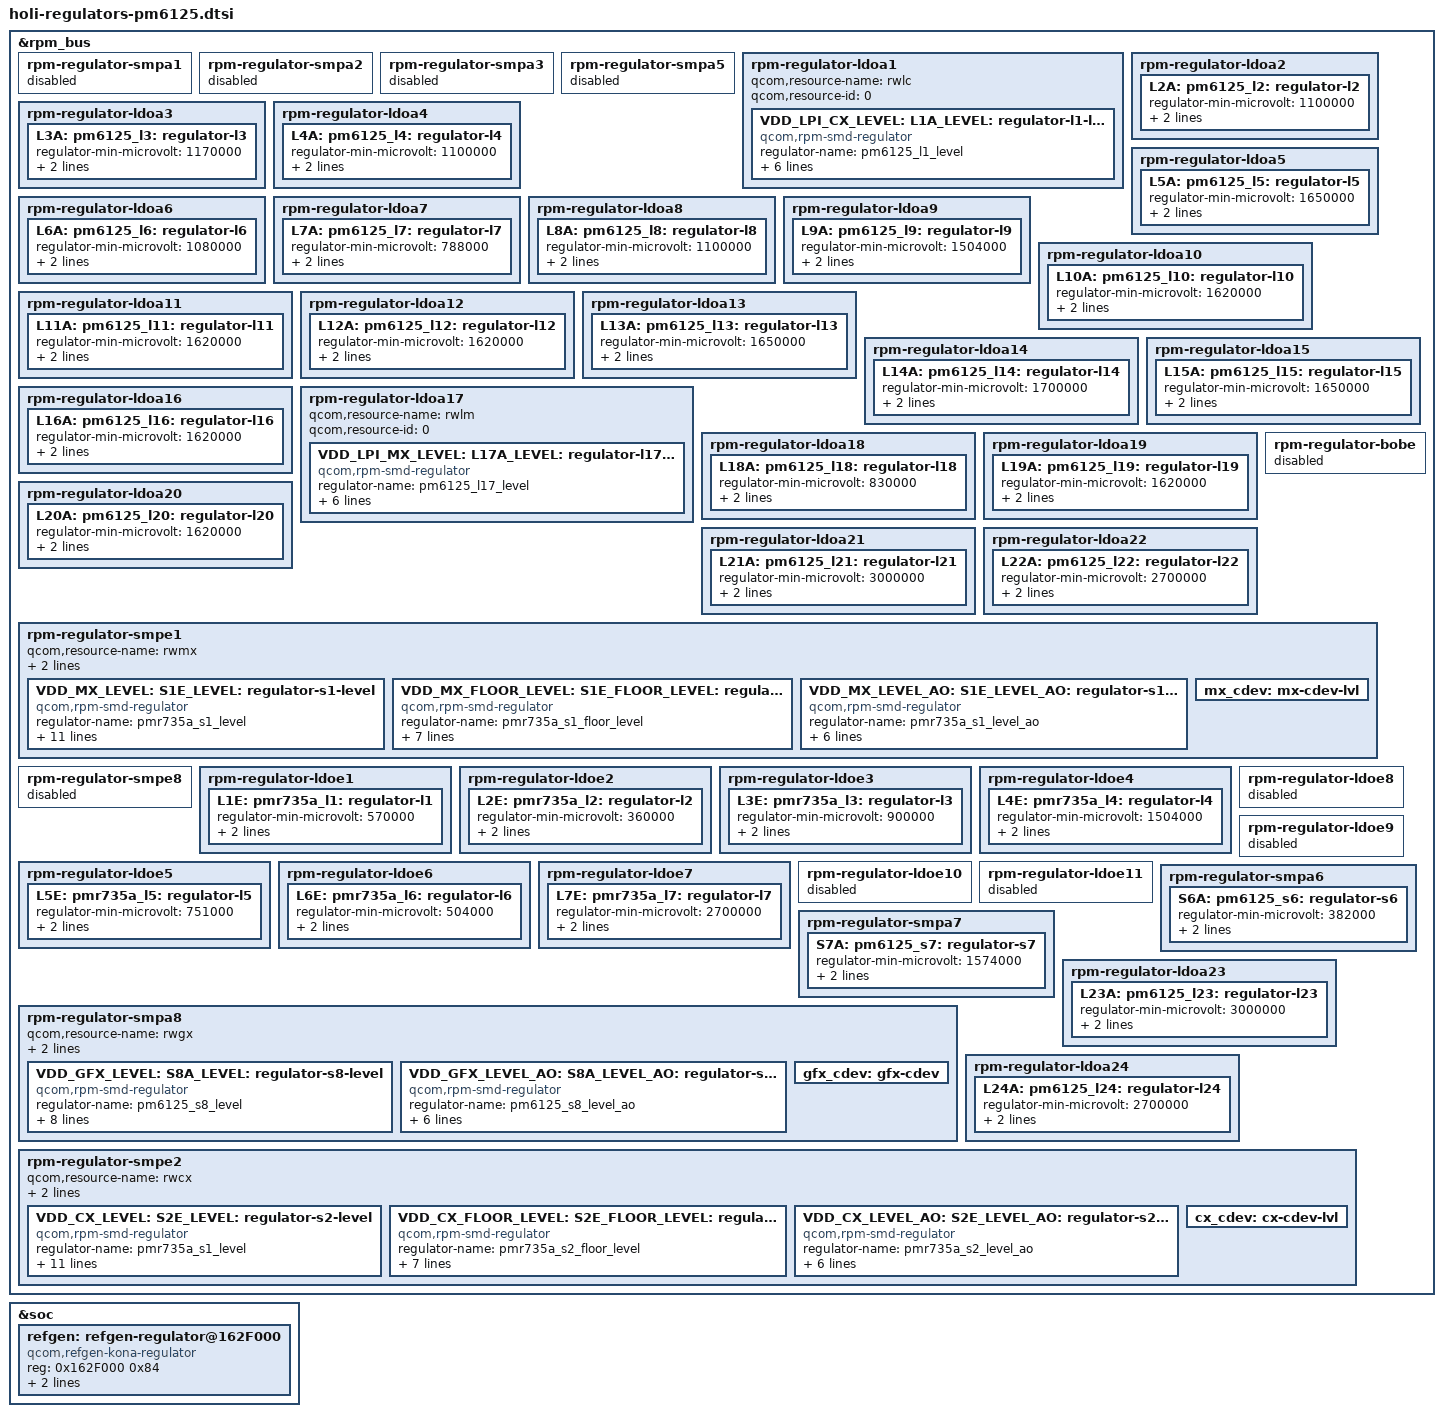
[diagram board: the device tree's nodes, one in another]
#include <dt-bindings/regulator/qcom,rpm-smd-regulator.h>

&rpm_bus {
	/* Delete all pm6350 and pm6150l nodes */
	/delete-node/ rpm-regulator-smpa1;
	/delete-node/ rpm-regulator-smpa2;
	/delete-node/ rpm-regulator-smpa3;
	/delete-node/ rpm-regulator-smpa5;
	/delete-node/ rpm-regulator-ldoa1;
	/delete-node/ rpm-regulator-ldoa2;
	/delete-node/ rpm-regulator-ldoa3;
	/delete-node/ rpm-regulator-ldoa4;
	/delete-node/ rpm-regulator-ldoa5;
	/delete-node/ rpm-regulator-ldoa6;
	/delete-node/ rpm-regulator-ldoa7;
	/delete-node/ rpm-regulator-ldoa8;
	/delete-node/ rpm-regulator-ldoa9;
	/delete-node/ rpm-regulator-ldoa10;
	/delete-node/ rpm-regulator-ldoa11;
	/delete-node/ rpm-regulator-ldoa12;
	/delete-node/ rpm-regulator-ldoa13;
	/delete-node/ rpm-regulator-ldoa14;
	/delete-node/ rpm-regulator-ldoa15;
	/delete-node/ rpm-regulator-ldoa16;
	/delete-node/ rpm-regulator-ldoa17;
	/delete-node/ rpm-regulator-ldoa18;
	/delete-node/ rpm-regulator-ldoa19;
	/delete-node/ rpm-regulator-ldoa20;
	/delete-node/ rpm-regulator-ldoa21;
	/delete-node/ rpm-regulator-ldoa22;
	/delete-node/ rpm-regulator-bobe;

	/delete-node/ rpm-regulator-smpe1;
	/delete-node/ rpm-regulator-smpe8;
	/delete-node/ rpm-regulator-ldoe1;
	/delete-node/ rpm-regulator-ldoe2;
	/delete-node/ rpm-regulator-ldoe3;
	/delete-node/ rpm-regulator-ldoe4;
	/delete-node/ rpm-regulator-ldoe5;
	/delete-node/ rpm-regulator-ldoe7;

	/* Disable PM6350 and PM6150L rpm-regulators */
	rpm-regulator-smpa1 {
		status = "disabled";
	};

	rpm-regulator-smpa2 {
		status = "disabled";
	};

	rpm-regulator-smpa3 {
		status = "disabled";
	};

	rpm-regulator-smpa5 {
		status = "disabled";
	};

	rpm-regulator-ldoa1 {
		status = "disabled";
	};

	rpm-regulator-ldoa2 {
		status = "disabled";
	};

	rpm-regulator-ldoa3 {
		status = "disabled";
	};

	rpm-regulator-ldoa4 {
		status = "disabled";
	};

	rpm-regulator-ldoa5 {
		status = "disabled";
	};

	rpm-regulator-ldoa6 {
		status = "disabled";
	};

	rpm-regulator-ldoa7 {
		status = "disabled";
	};

	rpm-regulator-ldoa8 {
		status = "disabled";
	};

	rpm-regulator-ldoa9 {
		status = "disabled";
	};

	rpm-regulator-ldoa10 {
		status = "disabled";
	};

	rpm-regulator-ldoa11 {
		status = "disabled";
	};

	rpm-regulator-ldoa12 {
		status = "disabled";
	};

	rpm-regulator-ldoa13 {
		status = "disabled";
	};

	rpm-regulator-ldoa14 {
		status = "disabled";
	};

	rpm-regulator-ldoa15 {
		status = "disabled";
	};

	rpm-regulator-ldoa16 {
		status = "disabled";
	};

	rpm-regulator-ldoa17 {
		status = "disabled";
	};

	rpm-regulator-ldoa18 {
		status = "disabled";
	};

	rpm-regulator-ldoa19 {
		status = "disabled";
	};

	rpm-regulator-ldoa20 {
		status = "disabled";
	};

	rpm-regulator-ldoa21 {
		status = "disabled";
	};

	rpm-regulator-ldoa22 {
		status = "disabled";
	};

	rpm-regulator-bobe {
		status = "disabled";
	};

	rpm-regulator-smpe1 {
		status = "disabled";
	};

	rpm-regulator-smpe8 {
		status = "disabled";
	};

	rpm-regulator-ldoe1 {
		status = "disabled";
	};

	rpm-regulator-ldoe2 {
		status = "disabled";
	};

	rpm-regulator-ldoe3 {
		status = "disabled";
	};

	rpm-regulator-ldoe4 {
		status = "disabled";
	};

	rpm-regulator-ldoe5 {
		status = "disabled";
	};

	rpm-regulator-ldoe6 {
		status = "disabled";
	};

	rpm-regulator-ldoe7 {
		status = "disabled";
	};

	rpm-regulator-ldoe8 {
		status = "disabled";
	};

	rpm-regulator-ldoe9 {
		status = "disabled";
	};

	rpm-regulator-ldoe10 {
		status = "disabled";
	};

	rpm-regulator-ldoe11 {
		status = "disabled";
	};
};

#include "pm6125-rpm-regulator.dtsi"
#include "pmr735a-rpm-regulator.dtsi"

&rpm_bus {
	rpm-regulator-smpa6 {
		status = "okay";
		S6A: pm6125_s6: regulator-s6 {
			regulator-min-microvolt = <382000>;
			regulator-max-microvolt = <1374000>;
			qcom,init-voltage = <1352000>;
			status = "okay";
		};
	};

	rpm-regulator-smpa7 {
		status = "okay";
		S7A: pm6125_s7: regulator-s7 {
			regulator-min-microvolt = <1574000>;
			regulator-max-microvolt = <2040000>;
			qcom,init-voltage = <2040000>;
			status = "okay";
		};
	};

	/* PM6125 S8 - VDD_GFX supply */
	rpm-regulator-smpa8 {
		status = "okay";
		qcom,resource-name = "rwgx";
		qcom,resource-id = <0>;
		qcom,always-wait-for-ack;
		VDD_GFX_LEVEL:
		S8A_LEVEL: pm6125_s8_level: regulator-s8-level {
			compatible = "qcom,rpm-smd-regulator";
			regulator-name = "pm6125_s8_level";
			qcom,set = <3>;
			regulator-min-microvolt =
					<RPM_SMD_REGULATOR_LEVEL_NONE>;
			regulator-max-microvolt =
					<RPM_SMD_REGULATOR_LEVEL_BINNING>;
			qcom,init-voltage-level =
				<RPM_SMD_REGULATOR_LEVEL_LOW_SVS>;
			qcom,use-voltage-level;
		};

		VDD_GFX_LEVEL_AO:
		S8A_LEVEL_AO: pm6125_s8_level_ao: regulator-s8-level-ao {
			compatible = "qcom,rpm-smd-regulator";
			regulator-name = "pm6125_s8_level_ao";
			qcom,set = <1>;
			regulator-min-microvolt =
					<RPM_SMD_REGULATOR_LEVEL_NONE>;
			regulator-max-microvolt =
					<RPM_SMD_REGULATOR_LEVEL_BINNING>;
			qcom,use-voltage-level;
		};

		/* Dummy node */
		gfx_cdev: gfx-cdev {
		};

	};

	/* VDD_LPI_CX supply */
	rpm-regulator-ldoa1 {
		status = "okay";
		qcom,resource-name = "rwlc";
		qcom,resource-id = <0>;
		VDD_LPI_CX_LEVEL:
		L1A_LEVEL: pm6125_l1_level: regulator-l1-level {
			compatible = "qcom,rpm-smd-regulator";
			regulator-name = "pm6125_l1_level";
			qcom,set = <3>;
			regulator-min-microvolt =
				<RPM_SMD_REGULATOR_LEVEL_RETENTION>;
			regulator-max-microvolt =
				<RPM_SMD_REGULATOR_LEVEL_BINNING>;
			qcom,use-voltage-level;
		};
	};

	rpm-regulator-ldoa2 {
		status = "okay";
		L2A: pm6125_l2: regulator-l2 {
			regulator-min-microvolt = <1100000>;
			regulator-max-microvolt = <1300000>;
			qcom,init-voltage = <1100000>;
			status = "okay";
		};
	};

	rpm-regulator-ldoa3 {
		status = "okay";
		L3A: pm6125_l3: regulator-l3 {
			regulator-min-microvolt = <1170000>;
			regulator-max-microvolt = <1304000>;
			qcom,init-voltage = <1170000>;
			status = "okay";
		};
	};

	rpm-regulator-ldoa4 {
		status = "okay";
		L4A: pm6125_l4: regulator-l4 {
			regulator-min-microvolt = <1100000>;
			regulator-max-microvolt = <1300000>;
			qcom,init-voltage = <1232000>;
			status = "okay";
		};
	};

	rpm-regulator-ldoa5 {
		status = "okay";
		L5A: pm6125_l5: regulator-l5 {
			regulator-min-microvolt = <1650000>;
			regulator-max-microvolt = <3050000>;
			qcom,init-voltage = <2960000>;
			status = "okay";
		};
	};

	rpm-regulator-ldoa6 {
		status = "okay";
		L6A: pm6125_l6: regulator-l6 {
			regulator-min-microvolt = <1080000>;
			regulator-max-microvolt = <1304000>;
			qcom,init-voltage = <1080000>;
			status = "okay";
		};
	};

	rpm-regulator-ldoa7 {
		status = "okay";
		L7A: pm6125_l7: regulator-l7 {
			regulator-min-microvolt = <788000>;
			regulator-max-microvolt = <1050000>;
			qcom,init-voltage = <880000>;
			status = "okay";
		};
	};

	rpm-regulator-ldoa8 {
		status = "okay";
		L8A: pm6125_l8: regulator-l8 {
			regulator-min-microvolt = <1100000>;
			regulator-max-microvolt = <1304000>;
			qcom,init-voltage = <1200000>;
			status = "okay";
		};
	};

	rpm-regulator-ldoa9 {
		status = "okay";
		L9A: pm6125_l9: regulator-l9 {
			regulator-min-microvolt = <1504000>;
			regulator-max-microvolt = <2000000>;
			qcom,init-voltage = <1800000>;
			status = "okay";
		};
	};

	rpm-regulator-ldoa10 {
		status = "okay";
		L10A: pm6125_l10: regulator-l10 {
			regulator-min-microvolt = <1620000>;
			regulator-max-microvolt = <1980000>;
			qcom,init-voltage = <1800000>;
			status = "okay";
		};
	};

	rpm-regulator-ldoa11 {
		status = "okay";
		L11A: pm6125_l11: regulator-l11 {
			regulator-min-microvolt = <1620000>;
			regulator-max-microvolt = <1980000>;
			qcom,init-voltage = <1800000>;
			status = "okay";
		};
	};

	rpm-regulator-ldoa12 {
		status = "okay";
		L12A: pm6125_l12: regulator-l12 {
			regulator-min-microvolt = <1620000>;
			regulator-max-microvolt = <2000000>;
			qcom,init-voltage = <1620000>;
			status = "okay";
		};
	};

	rpm-regulator-ldoa13 {
		status = "okay";
		L13A: pm6125_l13: regulator-l13 {
			regulator-min-microvolt = <1650000>;
			regulator-max-microvolt = <1980000>;
			qcom,init-voltage = <1650000>;
			status = "okay";
		};
	};

	rpm-regulator-ldoa14 {
		status = "okay";
		L14A: pm6125_l14: regulator-l14 {
			regulator-min-microvolt = <1700000>;
			regulator-max-microvolt = <1900000>;
			qcom,init-voltage = <1700000>;
			status = "okay";
		};
	};

	rpm-regulator-ldoa15 {
		status = "okay";
		L15A: pm6125_l15: regulator-l15 {
			regulator-min-microvolt = <1650000>;
			regulator-max-microvolt = <3544000>;
			qcom,init-voltage = <1650000>;
			status = "okay";
		};
	};

	rpm-regulator-ldoa16 {
		status = "okay";
		L16A: pm6125_l16: regulator-l16 {
			regulator-min-microvolt = <1620000>;
			regulator-max-microvolt = <1980000>;
			qcom,init-voltage = <1620000>;
			status = "okay";
		};
	};

	/* VDD_LPI_MX supply */
	rpm-regulator-ldoa17 {
		status = "okay";
		qcom,resource-name = "rwlm";
		qcom,resource-id = <0>;
		VDD_LPI_MX_LEVEL:
		L17A_LEVEL: pm6125_l17_level: regulator-l17-level {
			compatible = "qcom,rpm-smd-regulator";
			regulator-name = "pm6125_l17_level";
			qcom,set = <3>;
			regulator-min-microvolt =
				<RPM_SMD_REGULATOR_LEVEL_RETENTION>;
			regulator-max-microvolt =
				<RPM_SMD_REGULATOR_LEVEL_BINNING>;
			qcom,use-voltage-level;
		};
	};

	rpm-regulator-ldoa18 {
		status = "okay";
		L18A: pm6125_l18: regulator-l18 {
			regulator-min-microvolt = <830000>;
			regulator-max-microvolt = <920000>;
			qcom,init-voltage = <880000>;
			status = "okay";
		};
	};

	rpm-regulator-ldoa19 {
		status = "okay";
		L19A: pm6125_l19: regulator-l19 {
			regulator-min-microvolt = <1620000>;
			regulator-max-microvolt = <3300000>;
			qcom,init-voltage = <1620000>;
			status = "okay";
		};
	};

	rpm-regulator-ldoa20 {
		status = "okay";
		L20A: pm6125_l20: regulator-l20 {
			regulator-min-microvolt = <1620000>;
			regulator-max-microvolt = <3300000>;
			qcom,init-voltage = <1620000>;
			status = "okay";
		};
	};

	rpm-regulator-ldoa21 {
		status = "okay";
		L21A: pm6125_l21: regulator-l21 {
			regulator-min-microvolt = <3000000>;
			regulator-max-microvolt = <3400000>;
			qcom,init-voltage = <3000000>;
			status = "okay";
		};
	};

	rpm-regulator-ldoa22 {
		status = "okay";
		L22A: pm6125_l22: regulator-l22 {
			regulator-min-microvolt = <2700000>;
			regulator-max-microvolt = <3544000>;
			qcom,init-voltage = <2960000>;
			status = "okay";
		};
	};

	rpm-regulator-ldoa23 {
		status = "okay";
		L23A: pm6125_l23: regulator-l23 {
			regulator-min-microvolt = <3000000>;
			regulator-max-microvolt = <3400000>;
			qcom,init-voltage = <3000000>;
			status = "okay";
		};
	};

	rpm-regulator-ldoa24 {
		status = "okay";
		L24A: pm6125_l24: regulator-l24 {
			regulator-min-microvolt = <2700000>;
			regulator-max-microvolt = <3544000>;
			qcom,init-voltage = <2960000>;
			status = "okay";
		};
	};

	/* PMR735A S1E - VDD_MX supply */
	rpm-regulator-smpe1 {
		status = "okay";
		qcom,resource-name = "rwmx";
		qcom,resource-id = <0>;
		proxy-supply = <&VDD_MX_LEVEL>;
		VDD_MX_LEVEL:
		S1E_LEVEL: pmr735a_s1_level: regulator-s1-level {
			compatible = "qcom,rpm-smd-regulator";
			regulator-name = "pmr735a_s1_level";
			qcom,set = <3>;
			regulator-min-microvolt =
					<RPM_SMD_REGULATOR_LEVEL_RETENTION>;
			regulator-max-microvolt =
					<RPM_SMD_REGULATOR_LEVEL_BINNING>;
			qcom,init-voltage-level =
				<RPM_SMD_REGULATOR_LEVEL_TURBO>;
			qcom,proxy-consumer-enable;
			qcom,proxy-consumer-voltage =
				<RPM_SMD_REGULATOR_LEVEL_TURBO
				 RPM_SMD_REGULATOR_LEVEL_BINNING>;
			qcom,use-voltage-level;
		};

		VDD_MX_FLOOR_LEVEL:
		S1E_FLOOR_LEVEL:
		pmr735a_s1_floor_level: regulator-s1-floor-level {
			compatible = "qcom,rpm-smd-regulator";
			regulator-name = "pmr735a_s1_floor_level";
			qcom,set = <3>;
			regulator-min-microvolt =
					<RPM_SMD_REGULATOR_LEVEL_RETENTION>;
			regulator-max-microvolt =
					<RPM_SMD_REGULATOR_LEVEL_BINNING>;
			qcom,use-voltage-floor-level;
			qcom,always-send-voltage;
		};

		VDD_MX_LEVEL_AO:
		S1E_LEVEL_AO: pmr735a_s1_level_ao: regulator-s1-level-ao {
			compatible = "qcom,rpm-smd-regulator";
			regulator-name = "pmr735a_s1_level_ao";
			qcom,set = <1>;
			regulator-min-microvolt =
					<RPM_SMD_REGULATOR_LEVEL_RETENTION>;
			regulator-max-microvolt =
					<RPM_SMD_REGULATOR_LEVEL_BINNING>;
			qcom,use-voltage-level;
		};

		/* Dummy node */
		mx_cdev: mx-cdev-lvl {
		};
	};


	/* PMR735A S2E - VDD_CX supply */
	rpm-regulator-smpe2 {
		status = "okay";
		qcom,resource-name = "rwcx";
		qcom,resource-id = <0>;
		proxy-supply = <&VDD_CX_LEVEL>;
		VDD_CX_LEVEL:
		S2E_LEVEL: pmr735a_s2_level: regulator-s2-level {
			compatible = "qcom,rpm-smd-regulator";
			regulator-name = "pmr735a_s1_level";
			qcom,set = <3>;
			regulator-min-microvolt =
					<RPM_SMD_REGULATOR_LEVEL_RETENTION>;
			regulator-max-microvolt =
					<RPM_SMD_REGULATOR_LEVEL_BINNING>;
			qcom,init-voltage-level =
				<RPM_SMD_REGULATOR_LEVEL_TURBO>;
			qcom,proxy-consumer-enable;
			qcom,proxy-consumer-voltage =
				<RPM_SMD_REGULATOR_LEVEL_TURBO
				 RPM_SMD_REGULATOR_LEVEL_BINNING>;
			qcom,use-voltage-level;
		};

		VDD_CX_FLOOR_LEVEL:
		S2E_FLOOR_LEVEL:
		pmr735a_s2_floor_level: regulator-s2-floor-level {
			compatible = "qcom,rpm-smd-regulator";
			regulator-name = "pmr735a_s2_floor_level";
			qcom,set = <3>;
			regulator-min-microvolt =
					<RPM_SMD_REGULATOR_LEVEL_RETENTION>;
			regulator-max-microvolt =
					<RPM_SMD_REGULATOR_LEVEL_BINNING>;
			qcom,use-voltage-floor-level;
			qcom,always-send-voltage;
		};

		VDD_CX_LEVEL_AO:
		S2E_LEVEL_AO: pmr735a_s2_level_ao: regulator-s2-level-ao {
			compatible = "qcom,rpm-smd-regulator";
			regulator-name = "pmr735a_s2_level_ao";
			qcom,set = <1>;
			regulator-min-microvolt =
					<RPM_SMD_REGULATOR_LEVEL_RETENTION>;
			regulator-max-microvolt =
					<RPM_SMD_REGULATOR_LEVEL_BINNING>;
			qcom,use-voltage-level;
		};

		/* Dummy node */
		cx_cdev: cx-cdev-lvl {
		};
	};

	rpm-regulator-ldoe1 {
		status = "okay";
		L1E: pmr735a_l1: regulator-l1 {
			regulator-min-microvolt = <570000>;
			regulator-max-microvolt = <650000>;
			qcom,init-voltage = <600000>;
			status = "okay";
		};
	};

	rpm-regulator-ldoe2 {
		status = "okay";
		L2E: pmr735a_l2: regulator-l2 {
			regulator-min-microvolt = <360000>;
			regulator-max-microvolt = <752000>;
			qcom,init-voltage = <704000>;
			status = "okay";
		};
	};

	rpm-regulator-ldoe3 {
		status = "okay";
		L3E: pmr735a_l3: regulator-l3 {
			regulator-min-microvolt = <900000>;
			regulator-max-microvolt = <1200000>;
			qcom,init-voltage = <1128000>;
			status = "okay";
		};
	};

	rpm-regulator-ldoe4 {
		status = "okay";
		L4E: pmr735a_l4: regulator-l4 {
			regulator-min-microvolt = <1504000>;
			regulator-max-microvolt = <2000000>;
			qcom,init-voltage = <1504000>;
			status = "okay";
		};
	};

	rpm-regulator-ldoe5 {
		status = "okay";
		L5E: pmr735a_l5: regulator-l5 {
			regulator-min-microvolt = <751000>;
			regulator-max-microvolt = <824000>;
			qcom,init-voltage = <751000>;
			status = "okay";
		};
	};

	rpm-regulator-ldoe6 {
		status = "okay";
		L6E: pmr735a_l6: regulator-l6 {
			regulator-min-microvolt = <504000>;
			regulator-max-microvolt = <868000>;
			qcom,init-voltage = <504000>;
			status = "okay";
		};
	};

	rpm-regulator-ldoe7 {
		status = "okay";
		L7E: pmr735a_l7: regulator-l7 {
			regulator-min-microvolt = <2700000>;
			regulator-max-microvolt = <3300000>;
			qcom,init-voltage = <3080000>;
			status = "okay";
		};
	};
};

&soc {
	refgen: refgen-regulator@162F000 {
		compatible = "qcom,refgen-kona-regulator";
		reg = <0x162F000 0x84>;
		regulator-name = "refgen";
		regulator-enable-ramp-delay = <5>;
	};
};
